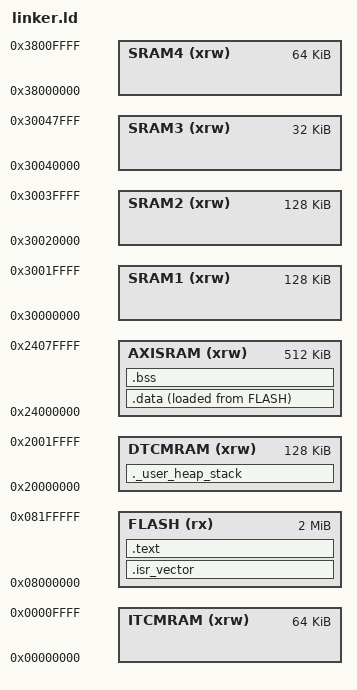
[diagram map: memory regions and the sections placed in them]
/* SPDX-License-Identifier: CC-BY-NC-4.0 */
/* Linker script for custom_h7_fc (STM32H743xx) */
/* Auto-generated by tools/generate_board.py */

ENTRY(Reset_Handler)

MEMORY
{
  FLASH (rx)      : ORIGIN = 0x08000000, LENGTH = 2048K
  DTCMRAM (xrw)   : ORIGIN = 0x20000000, LENGTH = 128K
  AXISRAM (xrw)   : ORIGIN = 0x24000000, LENGTH = 512K
  SRAM1 (xrw)     : ORIGIN = 0x30000000, LENGTH = 128K
  SRAM2 (xrw)     : ORIGIN = 0x30020000, LENGTH = 128K
  SRAM3 (xrw)     : ORIGIN = 0x30040000, LENGTH = 32K
  SRAM4 (xrw)     : ORIGIN = 0x38000000, LENGTH = 64K
  ITCMRAM (xrw)   : ORIGIN = 0x00000000, LENGTH = 64K
}

_estack = ORIGIN(DTCMRAM) + LENGTH(DTCMRAM);
_min_stack_size = 0x2000; /* 8 KB */
_min_heap_size  = 0x4000; /* 16 KB */

SECTIONS
{
  .isr_vector :
  {
    . = ALIGN(4);
    KEEP(*(.isr_vector))
    . = ALIGN(4);
  } >FLASH

  .text :
  {
    . = ALIGN(4);
    *(.text)
    *(.text*)
    *(.rodata)
    *(.rodata*)
    *(.glue_7)
    *(.glue_7t)
    *(.eh_frame)

    KEEP (*(.init))
    KEEP (*(.fini))

    . = ALIGN(4);
    _etext = .;
  } >FLASH

  _sidata = LOADADDR(.data);

  .data :
  {
    . = ALIGN(4);
    _sdata = .;
    *(.data)
    *(.data*)
    . = ALIGN(4);
    _edata = .;
  } >AXISRAM AT> FLASH

  .bss :
  {
    . = ALIGN(4);
    _sbss = .;
    *(.bss)
    *(.bss*)
    *(COMMON)
    . = ALIGN(4);
    _ebss = .;
  } >AXISRAM

  ._user_heap_stack :
  {
    . = ALIGN(8);
    PROVIDE ( end = . );
    PROVIDE ( _end = . );
    . = . + _min_heap_size;
    . = . + _min_stack_size;
    . = ALIGN(8);
  } >DTCMRAM
}
